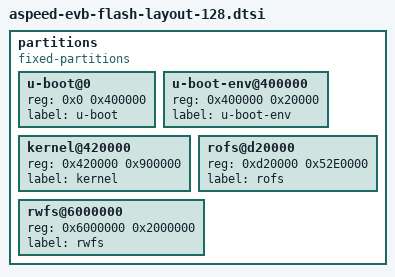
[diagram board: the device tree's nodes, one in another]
// SPDX-License-Identifier: GPL-2.0-only OR MIT

partitions {
	compatible = "fixed-partitions";
	#address-cells = <1>;
	#size-cells = <1>;

	u-boot@0 {
		reg = <0x0 0x400000>; // 4MB
		label = "u-boot";
	};

	u-boot-env@400000 {
		reg = <0x400000 0x20000>; // 128KB
		label = "u-boot-env";
	};

	kernel@420000 {
		reg = <0x420000 0x900000>; // 9MB
		label = "kernel";
	};

	rofs@d20000 {
		reg = <0xd20000 0x52E0000>; // 82.875MB
		label = "rofs";
	};

	rwfs@6000000 {
		reg = <0x6000000 0x2000000>; // 32MB
		label = "rwfs";
	};
};
